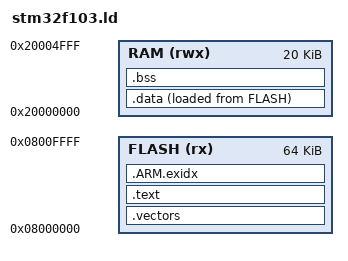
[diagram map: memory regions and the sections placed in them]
ENTRY(reset_handler)
MEMORY { FLASH (rx) : ORIGIN = 0x08000000, LENGTH = 64K
         RAM (rwx) : ORIGIN = 0x20000000, LENGTH = 20K }
_stack = ORIGIN(RAM)+LENGTH(RAM);
SECTIONS {
 .vectors : { KEEP(*(.vectors)) } > FLASH
 .text : { *(.text*) *(.rodata*) . = ALIGN(4); } > FLASH
 .ARM.exidx : { *(.ARM.exidx*) } > FLASH
 .data : { . = ALIGN(4); _data_start = .; *(.data*) . = ALIGN(4); _data_end = .; } > RAM AT> FLASH
 _data_load = LOADADDR(.data);
 .bss (NOLOAD) : { . = ALIGN(4); _bss_start = .; *(.bss*) *(COMMON) . = ALIGN(4); _bss_end = .; } > RAM
 ASSERT(_bss_end <= _stack - 2048, "Insufficient stack memory")
}
